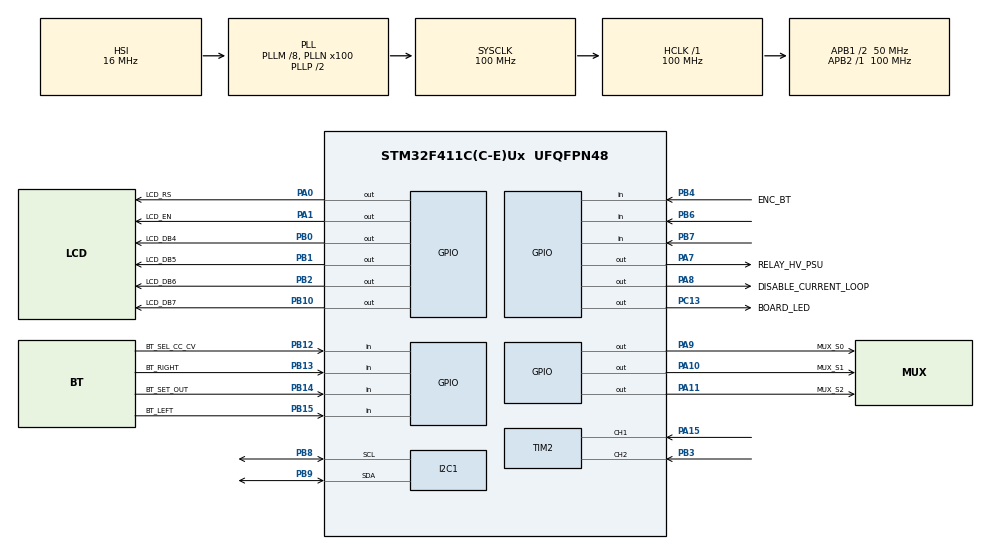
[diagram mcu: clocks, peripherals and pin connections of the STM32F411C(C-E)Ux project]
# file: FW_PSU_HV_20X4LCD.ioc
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FREERTOS.INCLUDE_vTaskDelayUntil=1
FREERTOS.Tasks01=defaultTask,0,128,StartDefaultTask,Default,NULL,Dynamic,NULL,NULL
FREERTOS.configUSE_NEWLIB_REENTRANT=1
Mcu.Family=STM32F4
Mcu.Name=STM32F411C(C-E)Ux
Mcu.Package=UFQFPN48
NVIC.PriorityGroup=NVIC_PRIORITYGROUP_4
NVIC.TIM1_UP_TIM10_IRQn=true\:15\:0\:false\:false\:true\:false\:false\:true\:true
NVIC.TimeBase=TIM1_UP_TIM10_IRQn
NVIC.TimeBaseIP=TIM10
PA0-WKUP.GPIO_Label=LCD_RS
PA0-WKUP.Signal=GPIO_Output
PA1.GPIO_Label=LCD_EN
PA1.GPIO_Speed=GPIO_SPEED_FREQ_LOW
PA1.Signal=GPIO_Output
PA10.GPIO_Label=MUX_S1
PA10.Signal=GPIO_Output
PA11.GPIO_Label=MUX_S2
PA11.Signal=GPIO_Output
PA13.Mode=Serial_Wire
PA13.Signal=SYS_JTMS-SWDIO
PA14.Mode=Serial_Wire
PA14.Signal=SYS_JTCK-SWCLK
PA15.Signal=S_TIM2_CH1_ETR
PA7.GPIO_Label=RELAY_HV_PSU
PA7.Signal=GPIO_Output
PA8.GPIO_Label=DISABLE_CURRENT_LOOP
PA8.Signal=GPIO_Output
PA9.GPIO_Label=MUX_S0
PA9.Signal=GPIO_Output
PB0.GPIO_Label=LCD_DB4
PB0.GPIO_Speed=GPIO_SPEED_FREQ_LOW
PB0.Signal=GPIO_Output
PB1.GPIO_Label=LCD_DB5
PB1.GPIO_Speed=GPIO_SPEED_FREQ_LOW
PB1.Signal=GPIO_Output
PB10.GPIO_Label=LCD_DB7
PB10.GPIO_Speed=GPIO_SPEED_FREQ_LOW
PB10.PinState=GPIO_PIN_RESET
PB10.Signal=GPIO_Output
PB12.GPIO_Label=BT_SEL_CC_CV
PB12.Signal=GPIO_Input
PB13.GPIO_Label=BT_RIGHT
PB13.Signal=GPIO_Input
PB14.GPIO_Label=BT_SET_OUT
PB14.Signal=GPIO_Input
PB15.GPIO_Label=BT_LEFT
PB15.Signal=GPIO_Input
PB2.GPIO_Label=LCD_DB6
PB2.GPIO_Speed=GPIO_SPEED_FREQ_LOW
PB2.Signal=GPIO_Output
PB3.Signal=S_TIM2_CH2
PB4.GPIO_Label=ENC_BT
PB4.Signal=GPIO_Input
PB6.Signal=GPIO_Input
PB7.Signal=GPIO_Input
PB8.Mode=I2C
PB8.Signal=I2C1_SCL
PB9.Mode=I2C
PB9.Signal=I2C1_SDA
PC13-ANTI_TAMP.GPIO_Label=BOARD_LED
PC13-ANTI_TAMP.Signal=GPIO_Output
PH0\ -\ OSC_IN.Mode=HSE-External-Oscillator
PH0\ -\ OSC_IN.Signal=RCC_OSC_IN
PH1\ -\ OSC_OUT.Mode=HSE-External-Oscillator
PH1\ -\ OSC_OUT.Signal=RCC_OSC_OUT
ProjectManager.HeapSize=0x200
ProjectManager.StackSize=0x400
ProjectManager.TargetToolchain=STM32CubeIDE
RCC.48MHZClocksFreq_Value=50000000
RCC.AHBFreq_Value=100000000
RCC.APB1CLKDivider=RCC_HCLK_DIV2
RCC.APB1Freq_Value=50000000
RCC.APB1TimFreq_Value=100000000
RCC.APB2Freq_Value=100000000
RCC.APB2TimFreq_Value=100000000
RCC.CortexFreq_Value=100000000
RCC.HCLKFreq_Value=100000000
RCC.HSE_VALUE=25000000
RCC.HSI_VALUE=16000000
RCC.LSE_VALUE=32768
RCC.PLLM=8
RCC.PLLN=100
RCC.SYSCLKFreq_VALUE=100000000
RCC.SYSCLKSource=RCC_SYSCLKSOURCE_PLLCLK
RCC.VCOOutputFreq_Value=200000000
SH.S_TIM2_CH1_ETR.0=TIM2_CH1,Encoder_Interface
SH.S_TIM2_CH2.0=TIM2_CH2,Encoder_Interface
TIM2.AutoReloadPreload=TIM_AUTORELOAD_PRELOAD_ENABLE
TIM2.EncoderMode=TIM_ENCODERMODE_TI12
TIM2.IC1Filter=12
VP_FREERTOS_VS_CMSIS_V1.Mode=CMSIS_V1
VP_SYS_VS_tim10.Mode=TIM10
board=custom

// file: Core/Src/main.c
/* USER CODE BEGIN Header */
/**
  ******************************************************************************
  * @file           : main.c
  * @brief          : Main program body
  ******************************************************************************
  * @attention
  *
  * Copyright (c) 2025 STMicroelectronics.
  * All rights reserved.
  *
  * This software is licensed under terms that can be found in the LICENSE file
  * in the root directory of this software component.
  * If no LICENSE file comes with this software, it is provided AS-IS.
  *
  ******************************************************************************
  */
/* USER CODE END Header */
#include "main.h"
#include "cmsis_os.h"

/* USER CODE BEGIN Includes */

#include "board.h"
#include "hmi.h"
#include "encoder.h"
#include "LCD_HD44780.h"
#include "dac.h"
#include "dac.h"

/* USER CODE END Includes */

I2C_HandleTypeDef hi2c1;

TIM_HandleTypeDef htim2;

osThreadId defaultTaskHandle;

void SystemClock_Config(void);
static void MX_GPIO_Init(void);
static void MX_TIM2_Init(void);
static void MX_I2C1_Init(void);
void StartDefaultTask(void const * argument);

int main(void)
{

  /* MCU Configuration--------------------------------------------------------*/

  /* Reset of all peripherals, Initializes the Flash interface and the Systick. */
  HAL_Init();

  /* Configure the system clock */
  SystemClock_Config();

  /* Initialize all configured peripherals */
  MX_GPIO_Init();
  MX_TIM2_Init();
  MX_I2C1_Init();
  /* USER CODE BEGIN 2 */

  HAL_TIM_Encoder_Start(&htim2, TIM_CHANNEL_ALL);

  /* USER CODE END 2 */

  /* Create the thread(s) */
  /* definition and creation of defaultTask */
  osThreadDef(defaultTask, StartDefaultTask, osPriorityNormal, 0, 128);
  defaultTaskHandle = osThreadCreate(osThread(defaultTask), NULL);

  /* Start scheduler */
  osKernelStart();

  /* We should never get here as control is now taken by the scheduler */

  /* Infinite loop */
  while (1)
  {

  }
}

void SystemClock_Config(void)
{
  RCC_OscInitTypeDef RCC_OscInitStruct = {0};
  RCC_ClkInitTypeDef RCC_ClkInitStruct = {0};

  /** Configure the main internal regulator output voltage
  */
  __HAL_RCC_PWR_CLK_ENABLE();
  __HAL_PWR_VOLTAGESCALING_CONFIG(PWR_REGULATOR_VOLTAGE_SCALE1);

  /** Initializes the RCC Oscillators according to the specified parameters
  * in the RCC_OscInitTypeDef structure.
  */
  RCC_OscInitStruct.OscillatorType = RCC_OSCILLATORTYPE_HSI;
  RCC_OscInitStruct.HSIState = RCC_HSI_ON;
  RCC_OscInitStruct.HSICalibrationValue = RCC_HSICALIBRATION_DEFAULT;
  RCC_OscInitStruct.PLL.PLLState = RCC_PLL_ON;
  RCC_OscInitStruct.PLL.PLLSource = RCC_PLLSOURCE_HSI;
  RCC_OscInitStruct.PLL.PLLM = 8;
  RCC_OscInitStruct.PLL.PLLN = 100;
  RCC_OscInitStruct.PLL.PLLP = RCC_PLLP_DIV2;
  RCC_OscInitStruct.PLL.PLLQ = 4;
  if (HAL_RCC_OscConfig(&RCC_OscInitStruct) != HAL_OK)
  {
    Error_Handler();
  }

  /** Initializes the CPU, AHB and APB buses clocks
  */
  RCC_ClkInitStruct.ClockType = RCC_CLOCKTYPE_HCLK|RCC_CLOCKTYPE_SYSCLK
                              |RCC_CLOCKTYPE_PCLK1|RCC_CLOCKTYPE_PCLK2;
  RCC_ClkInitStruct.SYSCLKSource = RCC_SYSCLKSOURCE_PLLCLK;
  RCC_ClkInitStruct.AHBCLKDivider = RCC_SYSCLK_DIV1;
  RCC_ClkInitStruct.APB1CLKDivider = RCC_HCLK_DIV2;
  RCC_ClkInitStruct.APB2CLKDivider = RCC_HCLK_DIV1;

  if (HAL_RCC_ClockConfig(&RCC_ClkInitStruct, FLASH_LATENCY_3) != HAL_OK)
  {
    Error_Handler();
  }
}

static void MX_I2C1_Init(void)
{

  hi2c1.Instance = I2C1;
  hi2c1.Init.ClockSpeed = 100000;
  hi2c1.Init.DutyCycle = I2C_DUTYCYCLE_2;
  hi2c1.Init.OwnAddress1 = 0;
  hi2c1.Init.AddressingMode = I2C_ADDRESSINGMODE_7BIT;
  hi2c1.Init.DualAddressMode = I2C_DUALADDRESS_DISABLE;
  hi2c1.Init.OwnAddress2 = 0;
  hi2c1.Init.GeneralCallMode = I2C_GENERALCALL_DISABLE;
  hi2c1.Init.NoStretchMode = I2C_NOSTRETCH_DISABLE;
  if (HAL_I2C_Init(&hi2c1) != HAL_OK)
  {
    Error_Handler();
  }

}

static void MX_TIM2_Init(void)
{

  TIM_Encoder_InitTypeDef sConfig = {0};
  TIM_MasterConfigTypeDef sMasterConfig = {0};

  htim2.Instance = TIM2;
  htim2.Init.Prescaler = 0;
  htim2.Init.CounterMode = TIM_COUNTERMODE_UP;
  htim2.Init.Period = 4294967295;
  htim2.Init.ClockDivision = TIM_CLOCKDIVISION_DIV1;
  htim2.Init.AutoReloadPreload = TIM_AUTORELOAD_PRELOAD_ENABLE;
  sConfig.EncoderMode = TIM_ENCODERMODE_TI12;
  sConfig.IC1Polarity = TIM_ICPOLARITY_RISING;
  sConfig.IC1Selection = TIM_ICSELECTION_DIRECTTI;
  sConfig.IC1Prescaler = TIM_ICPSC_DIV1;
  sConfig.IC1Filter = 12;
  sConfig.IC2Polarity = TIM_ICPOLARITY_RISING;
  sConfig.IC2Selection = TIM_ICSELECTION_DIRECTTI;
  sConfig.IC2Prescaler = TIM_ICPSC_DIV1;
  sConfig.IC2Filter = 0;
  if (HAL_TIM_Encoder_Init(&htim2, &sConfig) != HAL_OK)
  {
    Error_Handler();
  }
  sMasterConfig.MasterOutputTrigger = TIM_TRGO_RESET;
  sMasterConfig.MasterSlaveMode = TIM_MASTERSLAVEMODE_DISABLE;
  if (HAL_TIMEx_MasterConfigSynchronization(&htim2, &sMasterConfig) != HAL_OK)
  {
    Error_Handler();
  }

}

static void MX_GPIO_Init(void)
{
  GPIO_InitTypeDef GPIO_InitStruct = {0};

  /* GPIO Ports Clock Enable */
  __HAL_RCC_GPIOC_CLK_ENABLE();
  __HAL_RCC_GPIOH_CLK_ENABLE();
  __HAL_RCC_GPIOA_CLK_ENABLE();
  __HAL_RCC_GPIOB_CLK_ENABLE();

  /*Configure GPIO pin Output Level */
  HAL_GPIO_WritePin(BOARD_LED_GPIO_Port, BOARD_LED_Pin, GPIO_PIN_RESET);

  /*Configure GPIO pin Output Level */
  HAL_GPIO_WritePin(GPIOA, LCD_RS_Pin|LCD_EN_Pin|RELAY_HV_PSU_Pin|DISABLE_CURRENT_LOOP_Pin
                          |MUX_S0_Pin|MUX_S1_Pin|MUX_S2_Pin, GPIO_PIN_RESET);

  /*Configure GPIO pin Output Level */
  HAL_GPIO_WritePin(GPIOB, LCD_DB4_Pin|LCD_DB5_Pin|LCD_DB6_Pin|LCD_DB7_Pin, GPIO_PIN_RESET);

  /*Configure GPIO pin : BOARD_LED_Pin */
  GPIO_InitStruct.Pin = BOARD_LED_Pin;
  GPIO_InitStruct.Mode = GPIO_MODE_OUTPUT_PP;
  GPIO_InitStruct.Pull = GPIO_NOPULL;
  GPIO_InitStruct.Speed = GPIO_SPEED_FREQ_LOW;
  HAL_GPIO_Init(BOARD_LED_GPIO_Port, &GPIO_InitStruct);

  /*Configure GPIO pins : LCD_RS_Pin LCD_EN_Pin RELAY_HV_PSU_Pin DISABLE_CURRENT_LOOP_Pin
                           MUX_S0_Pin MUX_S1_Pin MUX_S2_Pin */
  GPIO_InitStruct.Pin = LCD_RS_Pin|LCD_EN_Pin|RELAY_HV_PSU_Pin|DISABLE_CURRENT_LOOP_Pin
                          |MUX_S0_Pin|MUX_S1_Pin|MUX_S2_Pin;
  GPIO_InitStruct.Mode = GPIO_MODE_OUTPUT_PP;
  GPIO_InitStruct.Pull = GPIO_NOPULL;
  GPIO_InitStruct.Speed = GPIO_SPEED_FREQ_LOW;
  HAL_GPIO_Init(GPIOA, &GPIO_InitStruct);

  /*Configure GPIO pins : LCD_DB4_Pin LCD_DB5_Pin LCD_DB6_Pin LCD_DB7_Pin */
  GPIO_InitStruct.Pin = LCD_DB4_Pin|LCD_DB5_Pin|LCD_DB6_Pin|LCD_DB7_Pin;
  GPIO_InitStruct.Mode = GPIO_MODE_OUTPUT_PP;
  GPIO_InitStruct.Pull = GPIO_NOPULL;
  GPIO_InitStruct.Speed = GPIO_SPEED_FREQ_LOW;
  HAL_GPIO_Init(GPIOB, &GPIO_InitStruct);

  /*Configure GPIO pins : BT_SEL_CC_CV_Pin BT_RIGHT_Pin BT_SET_OUT_Pin BT_LEFT_Pin
                           ENC_BT_Pin PB6 PB7 */
  GPIO_InitStruct.Pin = BT_SEL_CC_CV_Pin|BT_RIGHT_Pin|BT_SET_OUT_Pin|BT_LEFT_Pin
                          |ENC_BT_Pin|GPIO_PIN_6|GPIO_PIN_7;
  GPIO_InitStruct.Mode = GPIO_MODE_INPUT;
  GPIO_InitStruct.Pull = GPIO_NOPULL;
  HAL_GPIO_Init(GPIOB, &GPIO_InitStruct);

}

void StartDefaultTask(void const * argument)
{
  /* USER CODE BEGIN 5 */

  board_init();
  /* Infinite loop */
  for(;;)
  {
    //HAL_GPIO_TogglePin(BOARD_LED_GPIO_Port, BOARD_LED_Pin);

    vTaskDelay(100);
  }
  /* USER CODE END 5 */
}

void HAL_TIM_PeriodElapsedCallback(TIM_HandleTypeDef *htim)
{
  if (htim->Instance == TIM10)
  {
    HAL_IncTick();
  }
}

void Error_Handler(void)
{
  __disable_irq();
  while (1)
  {
  }
}
